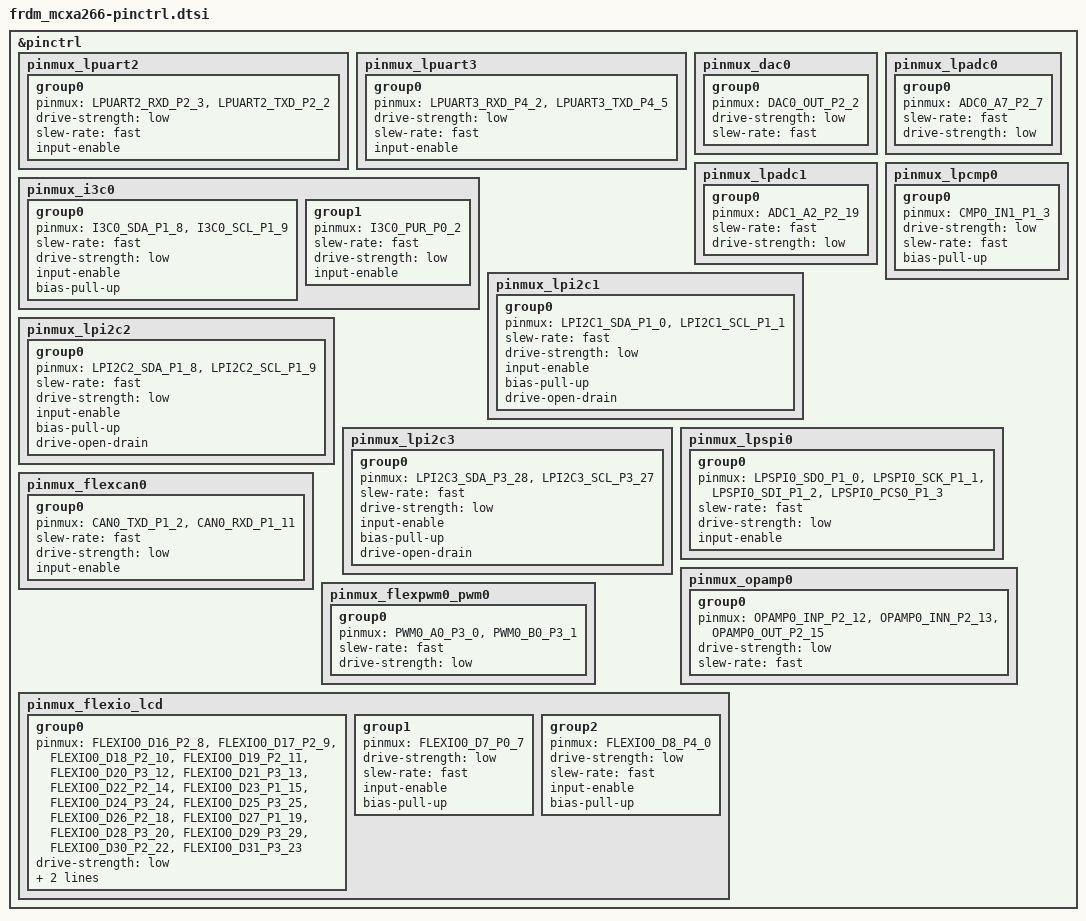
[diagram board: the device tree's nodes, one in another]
/*
 * Copyright 2025 NXP
 * SPDX-License-Identifier: Apache-2.0
 */

#include <nxp/mcx/MCXA266VLQ-pinctrl.h>

&pinctrl {
	pinmux_lpuart2: pinmux_lpuart2 {
		group0 {
			pinmux = <LPUART2_RXD_P2_3>,
				 <LPUART2_TXD_P2_2>;
			drive-strength = "low";
			slew-rate = "fast";
			input-enable;
		};
	};

	pinmux_lpuart3: pinmux_lpuart3 {
		group0 {
			pinmux = <LPUART3_RXD_P4_2>,
				 <LPUART3_TXD_P4_5>;
			drive-strength = "low";
			slew-rate = "fast";
			input-enable;
		};
	};

	pinmux_i3c0: pinmux_i3c0 {
		group0 {
			pinmux = <I3C0_SDA_P1_8>,
				 <I3C0_SCL_P1_9>;
			slew-rate = "fast";
			drive-strength = "low";
			input-enable;
			bias-pull-up;
		};

		group1 {
			pinmux = <I3C0_PUR_P0_2>;
			slew-rate = "fast";
			drive-strength = "low";
			input-enable;
		};
	};

	pinmux_dac0: pinmux_dac0 {
		group0 {
			pinmux = <DAC0_OUT_P2_2>;
			drive-strength = "low";
			slew-rate = "fast";
		};
	};

	pinmux_lpadc0: pinmux_lpadc0 {
		group0 {
			pinmux = <ADC0_A7_P2_7>;
			slew-rate = "fast";
			drive-strength = "low";
		};
	};

	pinmux_lpadc1: pinmux_lpadc1 {
		group0 {
			pinmux = <ADC1_A2_P2_19>;
			slew-rate = "fast";
			drive-strength = "low";
		};
	};

	pinmux_lpcmp0: pinmux_lpcmp0 {
		group0 {
			pinmux = <CMP0_IN1_P1_3>;
			drive-strength = "low";
			slew-rate = "fast";
			bias-pull-up;
		};
	};

	pinmux_lpi2c1: pinmux_lpi2c1 {
		group0 {
			pinmux = <LPI2C1_SDA_P1_0>,
				 <LPI2C1_SCL_P1_1>;
			slew-rate = "fast";
			drive-strength = "low";
			input-enable;
			bias-pull-up;
			drive-open-drain;
		};
	};

	pinmux_lpi2c2: pinmux_lpi2c2 {
		group0 {
			pinmux = <LPI2C2_SDA_P1_8>,
				 <LPI2C2_SCL_P1_9>;
			slew-rate = "fast";
			drive-strength = "low";
			input-enable;
			bias-pull-up;
			drive-open-drain;
		};
	};

	pinmux_lpi2c3: pinmux_lpi2c3 {
		group0 {
			pinmux = <LPI2C3_SDA_P3_28>,
				 <LPI2C3_SCL_P3_27>;
			slew-rate = "fast";
			drive-strength = "low";
			input-enable;
			bias-pull-up;
			drive-open-drain;
		};
	};

	pinmux_lpspi0: pinmux_lpspi0 {
		group0 {
			pinmux = <LPSPI0_SDO_P1_0>,
				 <LPSPI0_SCK_P1_1>,
				 <LPSPI0_SDI_P1_2>,
				 <LPSPI0_PCS0_P1_3>;
			slew-rate = "fast";
			drive-strength = "low";
			input-enable;
		};
	};

	pinmux_opamp0: pinmux_opamp0 {
		group0 {
			pinmux = <OPAMP0_INP_P2_12>,
				 <OPAMP0_INN_P2_13>,
				 <OPAMP0_OUT_P2_15>;
			drive-strength = "low";
			slew-rate = "fast";
		};
	};

	pinmux_flexcan0: pinmux_flexcan0 {
		group0 {
			pinmux = <CAN0_TXD_P1_2>,
				 <CAN0_RXD_P1_11>;
			slew-rate = "fast";
			drive-strength = "low";
			input-enable;
		};
	};

	pinmux_flexpwm0_pwm0: pinmux_flexpwm0_pwm0 {
		group0 {
			pinmux = <PWM0_A0_P3_0>,
				 <PWM0_B0_P3_1>;
			slew-rate = "fast";
			drive-strength = "low";
		};
	};

	pinmux_flexio_lcd: pinmux_flexio_lcd {
		group0 {
			pinmux = <FLEXIO0_D16_P2_8>,
				 <FLEXIO0_D17_P2_9>,
				 <FLEXIO0_D18_P2_10>,
				 <FLEXIO0_D19_P2_11>,
				 <FLEXIO0_D20_P3_12>,
				 <FLEXIO0_D21_P3_13>,
				 <FLEXIO0_D22_P2_14>,
				 <FLEXIO0_D23_P1_15>,
				 <FLEXIO0_D24_P3_24>,
				 <FLEXIO0_D25_P3_25>,
				 <FLEXIO0_D26_P2_18>,
				 <FLEXIO0_D27_P1_19>,
				 <FLEXIO0_D28_P3_20>,
				 <FLEXIO0_D29_P3_29>,
				 <FLEXIO0_D30_P2_22>,
				 <FLEXIO0_D31_P3_23>;
			drive-strength = "low";
			slew-rate = "fast";
			input-enable;
		};

		group1 {
			pinmux = <FLEXIO0_D7_P0_7>;
			drive-strength = "low";
			slew-rate = "fast";
			input-enable;
			bias-pull-up;
		};

		group2 {
			pinmux = <FLEXIO0_D8_P4_0>;
			drive-strength = "low";
			slew-rate = "fast";
			input-enable;
			bias-pull-up;
		};
	};
};
